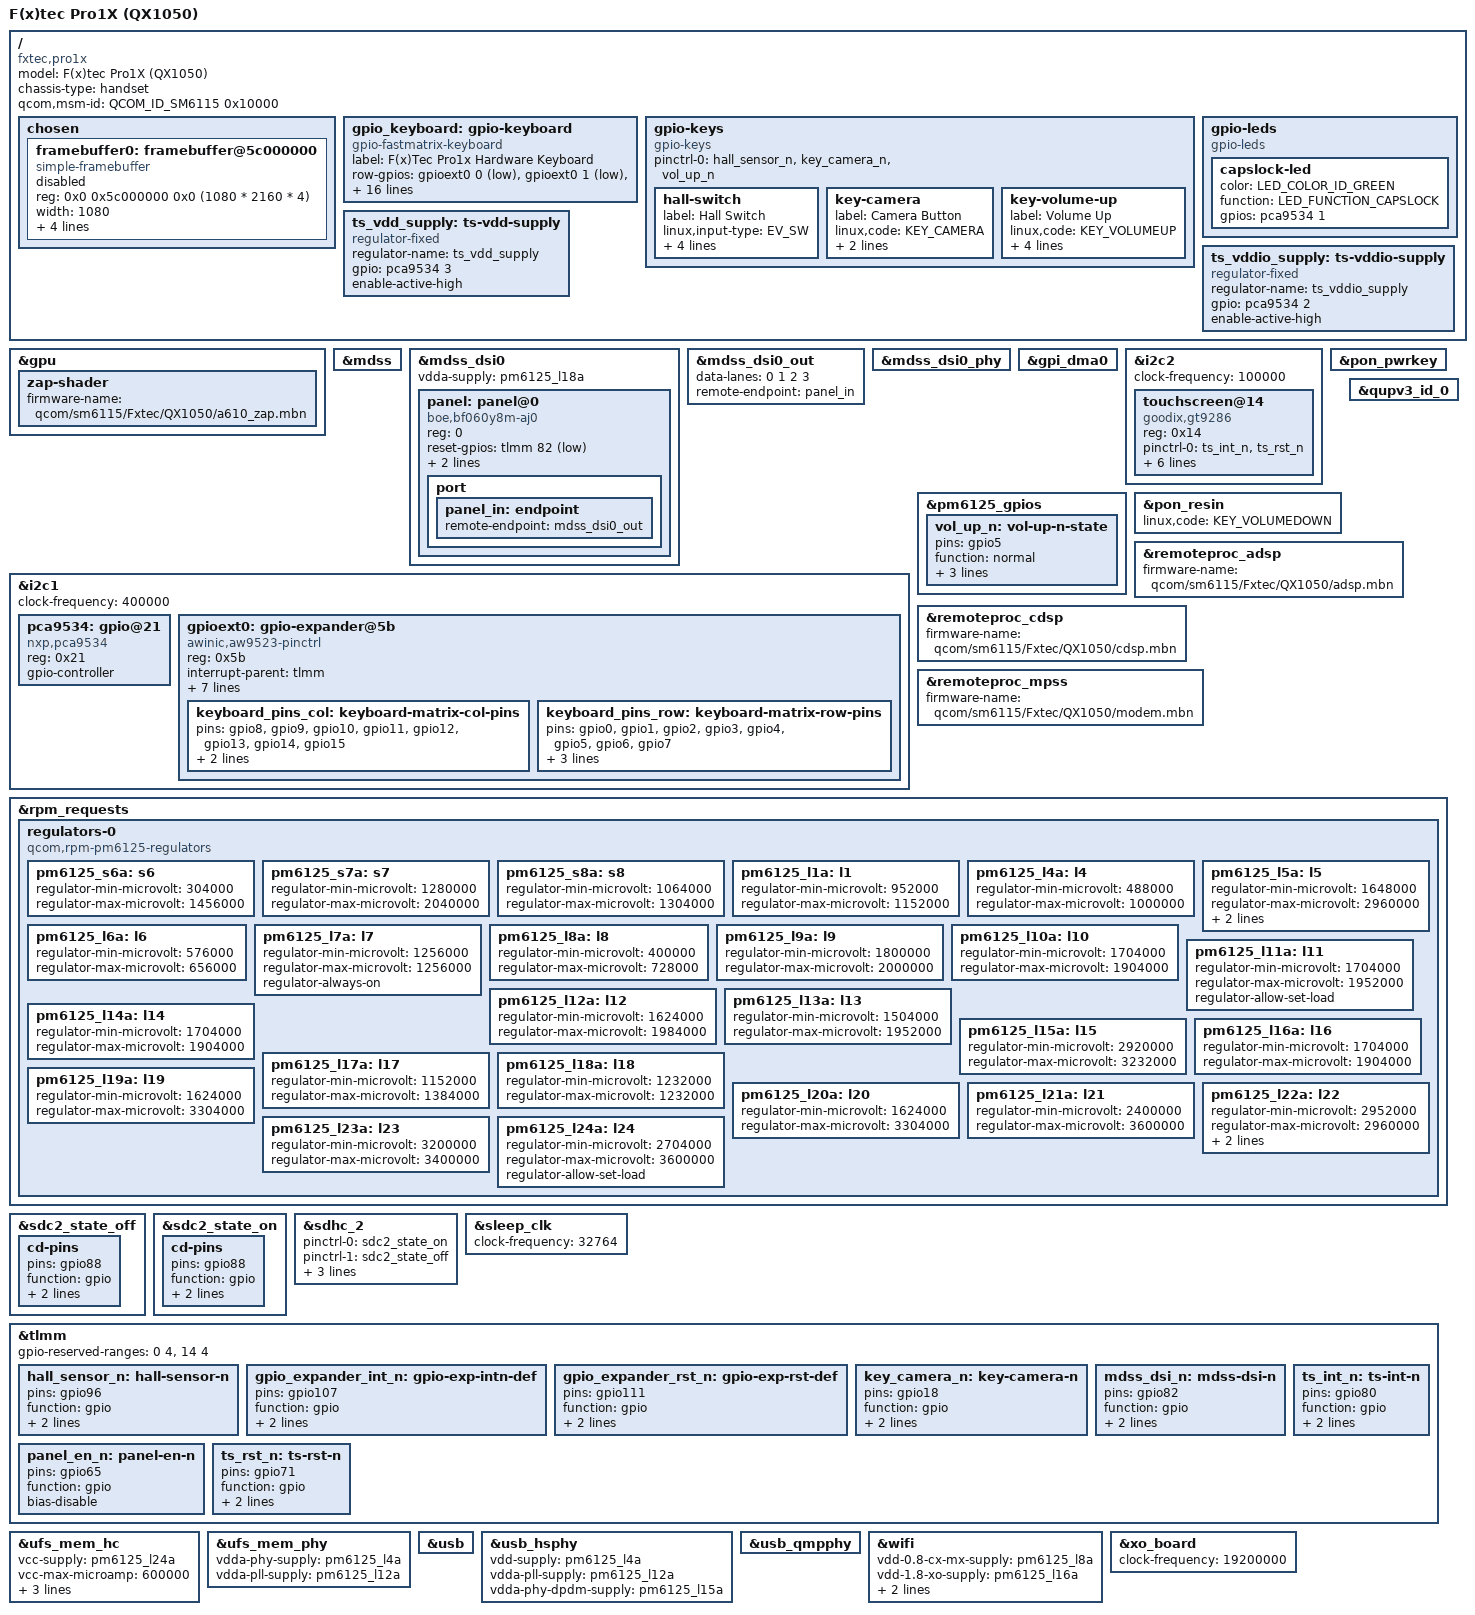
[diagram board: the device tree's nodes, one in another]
// SPDX-License-Identifier: (GPL-2.0+ OR BSD-3-Clause)
/*
 * Copyright (c) 2023, Dang Huynh <danct12@riseup.net>
 */

/dts-v1/;

#include "sm6115.dtsi"
#include "pm6125.dtsi"
#include <dt-bindings/arm/qcom,ids.h>
#include <dt-bindings/leds/common.h>
#include <dt-bindings/interrupt-controller/irq.h>

/ {
	model = "F(x)tec Pro1X (QX1050)";
	compatible = "fxtec,pro1x", "qcom,sm6115";
	chassis-type = "handset";

	qcom,msm-id = <QCOM_ID_SM6115 0x10000>;

	chosen {
		#address-cells = <2>;
		#size-cells = <2>;
		ranges;

		framebuffer0: framebuffer@5c000000 {
			compatible = "simple-framebuffer";
			reg = <0x0 0x5c000000 0x0 (1080 * 2160 * 4)>;
			width = <1080>;
			height = <2160>;
			stride = <(1080 * 4)>;
			format = "a8r8g8b8";
			clocks = <&gcc GCC_DISP_HF_AXI_CLK>;
			status = "disabled";
		};
	};

	gpio_keyboard: gpio-keyboard {
		compatible = "gpio-fastmatrix-keyboard";
		label = "F(x)Tec Pro1x Hardware Keyboard";
		row-gpios =
			<&gpioext0 0 (GPIO_ACTIVE_LOW | GPIO_OPEN_DRAIN)>,
			<&gpioext0 1 (GPIO_ACTIVE_LOW | GPIO_OPEN_DRAIN)>,
			<&gpioext0 2 (GPIO_ACTIVE_LOW | GPIO_OPEN_DRAIN)>,
			<&gpioext0 3 (GPIO_ACTIVE_LOW | GPIO_OPEN_DRAIN)>,
			<&gpioext0 4 (GPIO_ACTIVE_LOW | GPIO_OPEN_DRAIN)>,
			<&gpioext0 5 (GPIO_ACTIVE_LOW | GPIO_OPEN_DRAIN)>,
			<&gpioext0 6 (GPIO_ACTIVE_LOW | GPIO_OPEN_DRAIN)>,
			<&gpioext0 7 (GPIO_ACTIVE_LOW | GPIO_OPEN_DRAIN)>;
		col-gpios =
			<&gpioext0 8 GPIO_ACTIVE_LOW>,
			<&gpioext0 9 GPIO_ACTIVE_LOW>,
			<&gpioext0 10 GPIO_ACTIVE_LOW>,
			<&gpioext0 11 GPIO_ACTIVE_LOW>,
			<&gpioext0 12 GPIO_ACTIVE_LOW>,
			<&gpioext0 13 GPIO_ACTIVE_LOW>,
			<&gpioext0 14 GPIO_ACTIVE_LOW>,
			<&gpioext0 15 GPIO_ACTIVE_LOW>;

		keypad,num-rows = <8>;
		keypad,num-columns = <8>;
		pinctrl-names = "default";
		pinctrl-0 = <&keyboard_pins_col>, <&keyboard_pins_row>;
		autorescan-ms = <5>;
		debounce-delay-ms = <1>;
		col-scan-delay-us = <1500>;
	};

	gpio-keys {
		compatible = "gpio-keys";
		pinctrl-names = "default";
		pinctrl-0 = <&hall_sensor_n>, <&key_camera_n>, <&vol_up_n>;

		hall-switch {
			label = "Hall Switch";
			linux,input-type = <EV_SW>;
			linux,code = <SW_KEYPAD_SLIDE>;
			gpios = <&tlmm 96 GPIO_ACTIVE_HIGH>;
			debounce-interval = <90>;
			wakeup-source;
		};

		key-camera {
			label = "Camera Button";
			linux,code = <KEY_CAMERA>;
			gpios = <&tlmm 18 GPIO_ACTIVE_LOW>;
			debounce-interval = <15>;
		};

		key-volume-up {
			label = "Volume Up";
			linux,code = <KEY_VOLUMEUP>;
			gpios = <&pm6125_gpios 5 GPIO_ACTIVE_LOW>;
			debounce-interval = <15>;
			linux,can-disable;
			wakeup-source;
		};
	};

	gpio-leds {
		compatible = "gpio-leds";

		capslock-led {
			color = <LED_COLOR_ID_GREEN>;
			function = LED_FUNCTION_CAPSLOCK;
			gpios = <&pca9534 1 GPIO_ACTIVE_HIGH>;
		};
	};

	ts_vdd_supply: ts-vdd-supply {
		compatible = "regulator-fixed";
		regulator-name = "ts_vdd_supply";
		gpio = <&pca9534 3 GPIO_ACTIVE_HIGH>;
		enable-active-high;
	};

	ts_vddio_supply: ts-vddio-supply {
		compatible = "regulator-fixed";
		regulator-name = "ts_vddio_supply";
		gpio = <&pca9534 2 GPIO_ACTIVE_HIGH>;
		enable-active-high;
	};
};

&gpu {
	status = "okay";

	zap-shader {
		firmware-name = "qcom/sm6115/Fxtec/QX1050/a610_zap.mbn";
	};
};

&gpio_keyboard {
	linux,keymap = <
		MATRIX_KEY(0, 0, KEY_F1)    MATRIX_KEY(1, 0, KEY_H)
		MATRIX_KEY(2, 0, KEY_B)     MATRIX_KEY(3, 0, KEY_7)
		MATRIX_KEY(4, 0, KEY_UP)    MATRIX_KEY(5, 0, KEY_ENTER)
		MATRIX_KEY(6, 0, KEY_Y)     MATRIX_KEY(7, 0, KEY_COMMA)
		MATRIX_KEY(0, 1, KEY_3)     MATRIX_KEY(1, 1, KEY_S)
		MATRIX_KEY(2, 1, KEY_Z)     MATRIX_KEY(3, 1, KEY_M)
		MATRIX_KEY(4, 1, KEY_I)     MATRIX_KEY(5, 1, KEY_9)
		MATRIX_KEY(6, 1, KEY_W)     MATRIX_KEY(7, 1, KEY_J)
		MATRIX_KEY(0, 2, KEY_LEFT)  MATRIX_KEY(1, 2, KEY_G)
		MATRIX_KEY(2, 2, KEY_V)     MATRIX_KEY(3, 2, KEY_6)
		MATRIX_KEY(4, 2, KEY_RIGHT) MATRIX_KEY(5, 2, KEY_DELETE)
		MATRIX_KEY(6, 2, KEY_T)     MATRIX_KEY(7, 2, KEY_DOT)
		MATRIX_KEY(0, 3, KEY_SLASH) MATRIX_KEY(1, 3, KEY_A)
		MATRIX_KEY(2, 3, KEY_RIGHTBRACE) MATRIX_KEY(3, 3, KEY_HOMEPAGE)
		MATRIX_KEY(4, 3, KEY_P)     MATRIX_KEY(5, 3, KEY_MINUS)
		MATRIX_KEY(6, 3, KEY_Q)     MATRIX_KEY(7, 3, KEY_L)
		MATRIX_KEY(0, 4, KEY_BACKSPACE) MATRIX_KEY(1, 4, KEY_D)
		MATRIX_KEY(2, 4, KEY_X)     MATRIX_KEY(3, 4, KEY_K)
		MATRIX_KEY(4, 4, KEY_SEMICOLON) MATRIX_KEY(5, 4, KEY_EQUAL)
		MATRIX_KEY(6, 4, KEY_E)     MATRIX_KEY(7, 4, KEY_APOSTROPHE)
		MATRIX_KEY(0, 5, KEY_CAPSLOCK) MATRIX_KEY(1, 5, KEY_BACKSLASH)
		MATRIX_KEY(2, 5, KEY_LEFTBRACE) MATRIX_KEY(3, 5, KEY_DOWN)
		MATRIX_KEY(4, 5, KEY_O)     MATRIX_KEY(5, 5, KEY_0)
		MATRIX_KEY(6, 5, KEY_GRAVE) MATRIX_KEY(7, 5, KEY_K)
		MATRIX_KEY(0, 6, KEY_SPACE) MATRIX_KEY(1, 6, KEY_F)
		MATRIX_KEY(2, 6, KEY_C)     MATRIX_KEY(3, 6, KEY_N)
		MATRIX_KEY(4, 6, KEY_U)     MATRIX_KEY(5, 6, KEY_8)
		MATRIX_KEY(6, 6, KEY_R)     MATRIX_KEY(7, 6, KEY_5)
		MATRIX_KEY(0, 7, KEY_ESC)   MATRIX_KEY(1, 7, KEY_1)
		MATRIX_KEY(2, 7, KEY_RESERVED) MATRIX_KEY(3, 7, KEY_RESERVED)
		MATRIX_KEY(4, 7, KEY_2)     MATRIX_KEY(5, 7, KEY_4)

		MATRIX_KEY(6, 7, KEY_TAB)   MATRIX_KEY(7, 7, KEY_RESERVED)
	>;
};

&mdss {
	status = "okay";
};

&mdss_dsi0 {
	vdda-supply = <&pm6125_l18a>;
	status = "okay";

	panel: panel@0 {
		compatible = "boe,bf060y8m-aj0";
		reg = <0>;

		reset-gpios = <&tlmm 82 GPIO_ACTIVE_LOW>;

		vddio-supply = <&pm6125_l9a>;

		pinctrl-names = "default";
		pinctrl-0 = <&mdss_dsi_n &panel_en_n>;

		port {
			panel_in: endpoint {
				remote-endpoint = <&mdss_dsi0_out>;
			};
		};
	};
};

&mdss_dsi0_out {
	data-lanes = <0 1 2 3>;
	remote-endpoint = <&panel_in>;
};

&mdss_dsi0_phy {
	status = "okay";
};

&gpi_dma0 {
	status = "okay";
};

&i2c1 {
	status = "okay";
	/* Clock frequency was not specified downstream, let's park it to 100 KHz */
	clock-frequency = <400000>;

	pca9534: gpio@21 {
		compatible = "nxp,pca9534";
		reg = <0x21>;
		gpio-controller;
		#gpio-cells = <2>;
	};

	gpioext0: gpio-expander@5b {
		compatible = "awinic,aw9523-pinctrl";
		reg = <0x5b>;
		interrupt-parent = <&tlmm>;
		interrupts = <107 IRQ_TYPE_EDGE_FALLING>;
		gpio-controller;
		#gpio-cells = <2>;
		gpio-ranges = <&gpioext0 0 0 16>;
		interrupt-controller;
		#interrupt-cells = <2>;

		pinctrl-0 = <&gpio_expander_int_n>, <&gpio_expander_rst_n>;
		pinctrl-names = "default";
		reset-gpios = <&tlmm 111 GPIO_ACTIVE_HIGH>;

		keyboard_pins_col: keyboard-matrix-col-pins {
			pins = "gpio8", "gpio9", "gpio10", "gpio11",
			       "gpio12", "gpio13", "gpio14", "gpio15";
			function = "gpio";
			output-low;
		};

		keyboard_pins_row: keyboard-matrix-row-pins {
			pins = "gpio0", "gpio1", "gpio2", "gpio3",
			       "gpio4", "gpio5", "gpio6", "gpio7";
			function = "gpio";
			drive-open-drain;
			input-enable;
		};
	};
};

&i2c2 {
	status = "okay";
	/* Clock frequency was not specified downstream, let's park it to 100 KHz */
	clock-frequency = <100000>;

	touchscreen@14 {
		compatible = "goodix,gt9286";
		reg = <0x14>;
		pinctrl-names = "default";
		pinctrl-0 = <&ts_int_n>, <&ts_rst_n>;

		interrupt-parent = <&tlmm>;
		interrupts = <80 IRQ_TYPE_LEVEL_LOW>;

		irq-gpios = <&tlmm 80 IRQ_TYPE_LEVEL_LOW>;
		reset-gpios = <&tlmm 71 GPIO_ACTIVE_HIGH>;
		AVDD28-supply = <&ts_vdd_supply>;
		VDDIO-supply = <&ts_vddio_supply>;
	};
};

&pm6125_gpios {
	vol_up_n: vol-up-n-state {
		pins = "gpio5";
		function = "normal";
		power-source = <0>;
		bias-pull-up;
		input-enable;
	};
};

&pon_pwrkey {
	status = "okay";
};

&pon_resin {
	linux,code = <KEY_VOLUMEDOWN>;
	status = "okay";
};

&qupv3_id_0 {
	status = "okay";
};

&remoteproc_adsp {
	firmware-name = "qcom/sm6115/Fxtec/QX1050/adsp.mbn";
	status = "okay";
};

&remoteproc_cdsp {
	firmware-name = "qcom/sm6115/Fxtec/QX1050/cdsp.mbn";
	status = "okay";
};

&remoteproc_mpss {
	firmware-name = "qcom/sm6115/Fxtec/QX1050/modem.mbn";
	status = "okay";
};

&rpm_requests {
	regulators-0 {
		compatible = "qcom,rpm-pm6125-regulators";

		pm6125_s6a: s6 {
			regulator-min-microvolt = <304000>;
			regulator-max-microvolt = <1456000>;
		};

		pm6125_s7a: s7 {
			regulator-min-microvolt = <1280000>;
			regulator-max-microvolt = <2040000>;
		};

		pm6125_s8a: s8 {
			regulator-min-microvolt = <1064000>;
			regulator-max-microvolt = <1304000>;
		};

		pm6125_l1a: l1 {
			regulator-min-microvolt = <952000>;
			regulator-max-microvolt = <1152000>;
		};

		pm6125_l4a: l4 {
			regulator-min-microvolt = <488000>;
			regulator-max-microvolt = <1000000>;
		};

		pm6125_l5a: l5 {
			regulator-min-microvolt = <1648000>;
			/* 3.056V capped to 2.96V for SDHCI */
			regulator-max-microvolt = <2960000>;
			regulator-allow-set-load;
			/* Broken hw, this one can't be turned off or SDHCI will break! */
			regulator-always-on;
		};

		pm6125_l6a: l6 {
			regulator-min-microvolt = <576000>;
			regulator-max-microvolt = <656000>;
		};

		pm6125_l7a: l7 {
			/* 1.2V-1.304V fixed at 1.256V for SDHCI bias */
			regulator-min-microvolt = <1256000>;
			regulator-max-microvolt = <1256000>;
			/*
			 * TODO: SDHCI seems to also work with this one turned off, however
			 * there exists a possibility that it may not work with some very
			 * specific SDCard types, perhaps validating this against a wide
			 * range of models could rule that out, saving some power would
			 * certainly be nice..
			 */
			regulator-always-on;
		};

		pm6125_l8a: l8 {
			regulator-min-microvolt = <400000>;
			regulator-max-microvolt = <728000>;
		};

		pm6125_l9a: l9 {
			regulator-min-microvolt = <1800000>;
			regulator-max-microvolt = <2000000>;
		};

		pm6125_l10a: l10 {
			regulator-min-microvolt = <1704000>;
			regulator-max-microvolt = <1904000>;
		};

		pm6125_l11a: l11 {
			regulator-min-microvolt = <1704000>;
			regulator-max-microvolt = <1952000>;
			regulator-allow-set-load;
		};

		pm6125_l12a: l12 {
			regulator-min-microvolt = <1624000>;
			regulator-max-microvolt = <1984000>;
		};

		pm6125_l13a: l13 {
			regulator-min-microvolt = <1504000>;
			regulator-max-microvolt = <1952000>;
		};

		pm6125_l14a: l14 {
			regulator-min-microvolt = <1704000>;
			regulator-max-microvolt = <1904000>;
		};

		pm6125_l15a: l15 {
			regulator-min-microvolt = <2920000>;
			regulator-max-microvolt = <3232000>;
		};

		pm6125_l16a: l16 {
			regulator-min-microvolt = <1704000>;
			regulator-max-microvolt = <1904000>;
		};

		pm6125_l17a: l17 {
			regulator-min-microvolt = <1152000>;
			regulator-max-microvolt = <1384000>;
		};

		pm6125_l18a: l18 {
			/* 1.104V-1.312V fixed @ 1.232V for DSIPHY */
			regulator-min-microvolt = <1232000>;
			regulator-max-microvolt = <1232000>;
		};

		pm6125_l19a: l19 {
			regulator-min-microvolt = <1624000>;
			regulator-max-microvolt = <3304000>;
		};

		pm6125_l20a: l20 {
			regulator-min-microvolt = <1624000>;
			regulator-max-microvolt = <3304000>;
		};

		pm6125_l21a: l21 {
			regulator-min-microvolt = <2400000>;
			regulator-max-microvolt = <3600000>;
		};

		pm6125_l22a: l22 {
			regulator-min-microvolt = <2952000>;
			/* 3.304V capped to 2.96V for SDHCI */
			regulator-max-microvolt = <2960000>;
			regulator-allow-set-load;
			/* Broken hw, this one can't be turned off or SDHCI will break! */
			regulator-always-on;
		};

		pm6125_l23a: l23 {
			regulator-min-microvolt = <3200000>;
			regulator-max-microvolt = <3400000>;
		};

		pm6125_l24a: l24 {
			regulator-min-microvolt = <2704000>;
			regulator-max-microvolt = <3600000>;
			regulator-allow-set-load;
		};
	};
};

&sdc2_state_off {
	cd-pins {
		pins = "gpio88";
		function = "gpio";
		drive-strength = <2>;
		bias-disable;
	};
};

&sdc2_state_on {
	cd-pins {
		pins = "gpio88";
		function = "gpio";
		drive-strength = <2>;
		bias-pull-up;
	};
};

&sdhc_2 {
	pinctrl-names = "default", "sleep";
	pinctrl-0 = <&sdc2_state_on>;
	pinctrl-1 = <&sdc2_state_off>;

	cd-gpios = <&tlmm 88 GPIO_ACTIVE_LOW>;

	vmmc-supply = <&pm6125_l22a>;
	vqmmc-supply = <&pm6125_l5a>;
	status = "okay";
};

&sleep_clk {
	clock-frequency = <32764>;
};

&tlmm {
	gpio-reserved-ranges = <0 4>, <14 4>;

	hall_sensor_n: hall-sensor-n {
		pins = "gpio96";
		function = "gpio";
		drive-strength = <2>;
		bias-pull-up;
	};

	gpio_expander_int_n: gpio-exp-intn-def {
		pins = "gpio107";
		function = "gpio";
		drive-strength = <2>;
		input-enable;
	};
	gpio_expander_rst_n: gpio-exp-rst-def {
		pins = "gpio111";
		function = "gpio";
		drive-strength = <8>;
		bias-disable;
	};

	key_camera_n: key-camera-n {
		pins = "gpio18";
		function = "gpio";
		drive-strength = <2>;
		bias-pull-up;
	};

	mdss_dsi_n: mdss-dsi-n {
		pins = "gpio82";
		function = "gpio";
		drive-strength = <8>;
		bias-disable;
	};

	panel_en_n: panel-en-n {
		pins = "gpio65";
		function = "gpio";
		bias-disable;
	};

	ts_int_n: ts-int-n {
		pins = "gpio80";
		function = "gpio";
		drive-strength = <8>;
		bias-pull-up;
	};

	ts_rst_n: ts-rst-n {
		pins = "gpio71";
		function = "gpio";
		drive-strength = <8>;
		bias-pull-up;
	};
};

&ufs_mem_hc {
	vcc-supply = <&pm6125_l24a>;
	vcc-max-microamp = <600000>;
	vccq2-supply = <&pm6125_l11a>;
	vccq2-max-microamp = <600000>;
	vdd-hba-supply = <&pm6125_l18a>;
	status = "okay";
};

&ufs_mem_phy {
	vdda-phy-supply = <&pm6125_l4a>;
	vdda-pll-supply = <&pm6125_l12a>;
	status = "okay";
};

&usb {
	status = "okay";
};

&usb_hsphy {
	vdd-supply = <&pm6125_l4a>;
	vdda-pll-supply = <&pm6125_l12a>;
	vdda-phy-dpdm-supply = <&pm6125_l15a>;
	status = "okay";
};

&usb_qmpphy {
	status = "okay";
};

&wifi {
	vdd-0.8-cx-mx-supply = <&pm6125_l8a>;
	vdd-1.8-xo-supply = <&pm6125_l16a>;
	vdd-1.3-rfa-supply = <&pm6125_l17a>;
	vdd-3.3-ch0-supply = <&pm6125_l23a>;

	status = "okay";
};

&xo_board {
	clock-frequency = <19200000>;
};
